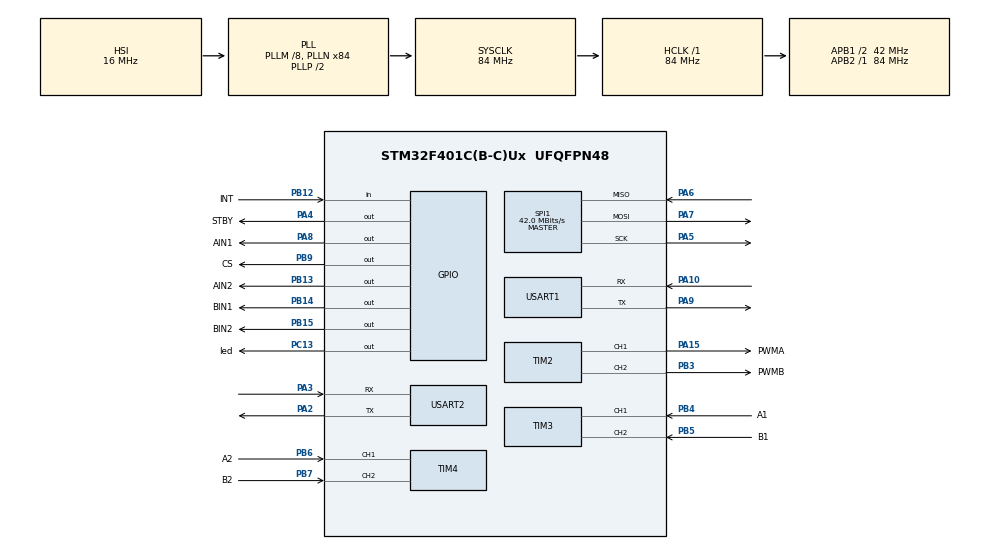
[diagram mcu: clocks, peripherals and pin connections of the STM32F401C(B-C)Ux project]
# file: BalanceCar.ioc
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Mcu.Family=STM32F4
Mcu.Name=STM32F401C(B-C)Ux
Mcu.Package=UFQFPN48
NVIC.PriorityGroup=NVIC_PRIORITYGROUP_4
PA10.Mode=Asynchronous
PA10.Signal=USART1_RX
PA15.GPIO_Label=PWMA
PA15.Signal=S_TIM2_CH1_ETR
PA2.Mode=Asynchronous
PA2.Signal=USART2_TX
PA3.Mode=Asynchronous
PA3.Signal=USART2_RX
PA4.GPIO_Label=STBY
PA4.Signal=GPIO_Output
PA5.Mode=Full_Duplex_Master
PA5.Signal=SPI1_SCK
PA6.Mode=Full_Duplex_Master
PA6.Signal=SPI1_MISO
PA7.Mode=Full_Duplex_Master
PA7.Signal=SPI1_MOSI
PA8.GPIO_Label=AIN1
PA8.Signal=GPIO_Output
PA9.Mode=Asynchronous
PA9.Signal=USART1_TX
PB12.GPIO_Label=INT
PB12.GPIO_PuPd=GPIO_PULLUP
PB12.Signal=GPIO_Input
PB13.GPIO_Label=AIN2
PB13.Signal=GPIO_Output
PB14.GPIO_Label=BIN1
PB14.Signal=GPIO_Output
PB15.GPIO_Label=BIN2
PB15.Signal=GPIO_Output
PB3.GPIO_Label=PWMB
PB3.Signal=S_TIM2_CH2
PB4.GPIO_Label=A1
PB4.Signal=S_TIM3_CH1
PB5.GPIO_Label=B1
PB5.Signal=S_TIM3_CH2
PB6.GPIO_Label=A2
PB6.Signal=S_TIM4_CH1
PB7.GPIO_Label=B2
PB7.Signal=S_TIM4_CH2
PB9.GPIO_Label=CS
PB9.Signal=GPIO_Output
PC13-ANTI_TAMP.GPIO_Label=led
PC13-ANTI_TAMP.Signal=GPIO_Output
PC14-OSC32_IN.Mode=LSE-External-Oscillator
PC14-OSC32_IN.Signal=RCC_OSC32_IN
PC15-OSC32_OUT.Mode=LSE-External-Oscillator
PC15-OSC32_OUT.Signal=RCC_OSC32_OUT
PH0\ -\ OSC_IN.Mode=HSE-External-Oscillator
PH0\ -\ OSC_IN.Signal=RCC_OSC_IN
PH1\ -\ OSC_OUT.Mode=HSE-External-Oscillator
PH1\ -\ OSC_OUT.Signal=RCC_OSC_OUT
ProjectManager.HeapSize=0x200
ProjectManager.StackSize=0x400
ProjectManager.TargetToolchain=Makefile
RCC.48MHZClocksFreq_Value=42000000
RCC.AHBFreq_Value=84000000
RCC.APB1CLKDivider=RCC_HCLK_DIV2
RCC.APB1Freq_Value=42000000
RCC.APB1TimFreq_Value=84000000
RCC.APB2Freq_Value=84000000
RCC.APB2TimFreq_Value=84000000
RCC.CortexFreq_Value=84000000
RCC.HCLKFreq_Value=84000000
RCC.HSE_VALUE=25000000
RCC.HSI_VALUE=16000000
RCC.PLLM=8
RCC.PLLN=84
RCC.SYSCLKFreq_VALUE=84000000
RCC.SYSCLKSource=RCC_SYSCLKSOURCE_PLLCLK
RCC.VCOOutputFreq_Value=168000000
SH.S_TIM2_CH1_ETR.0=TIM2_CH1,PWM Generation1 CH1
SH.S_TIM2_CH2.0=TIM2_CH2,PWM Generation2 CH2
SH.S_TIM3_CH1.0=TIM3_CH1,Encoder_Interface
SH.S_TIM3_CH2.0=TIM3_CH2,Encoder_Interface
SH.S_TIM4_CH1.0=TIM4_CH1,Encoder_Interface
SH.S_TIM4_CH2.0=TIM4_CH2,Encoder_Interface
SPI1.CalculateBaudRate=42.0 MBits/s
SPI1.Direction=SPI_DIRECTION_2LINES
SPI1.Mode=SPI_MODE_MASTER
SPI1.VirtualType=VM_MASTER
TIM2.Channel-PWM\ Generation1\ CH1=TIM_CHANNEL_1
TIM2.Channel-PWM\ Generation2\ CH2=TIM_CHANNEL_2
USART1.VirtualMode=VM_ASYNC
USART2.VirtualMode=VM_ASYNC
board=custom

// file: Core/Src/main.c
/* USER CODE BEGIN Header */
/**
  ******************************************************************************
  * @file           : main.c
  * @brief          : Main program body
  ******************************************************************************
  * @attention
  *
  * Copyright (c) 2024 STMicroelectronics.
  * All rights reserved.
  *
  * This software is licensed under terms that can be found in the LICENSE file
  * in the root directory of this software component.
  * If no LICENSE file comes with this software, it is provided AS-IS.
  *
  ******************************************************************************
  */
/* USER CODE END Header */
#include "main.h"
#include "spi.h"
#include "tim.h"
#include "usart.h"
#include "gpio.h"
#include "stdio.h"

void SystemClock_Config(void);

int main(void)
{

  /* MCU Configuration--------------------------------------------------------*/

  /* Reset of all peripherals, Initializes the Flash interface and the Systick. */
  HAL_Init();

  /* Configure the system clock */
  SystemClock_Config();

  /* Initialize all configured peripherals */
  MX_GPIO_Init();
  MX_SPI1_Init();
  MX_TIM2_Init();
  MX_TIM3_Init();
  MX_TIM4_Init();
  MX_USART1_UART_Init();
  MX_USART2_UART_Init();

  /* Infinite loop */
  /* USER CODE BEGIN WHILE */
  while (1)
  {

      printf("HELLO\n");
      HAL_Delay(1000);
    /* USER CODE END WHILE */

  }
}

void SystemClock_Config(void)
{
  RCC_OscInitTypeDef RCC_OscInitStruct = {0};
  RCC_ClkInitTypeDef RCC_ClkInitStruct = {0};

  /** Configure the main internal regulator output voltage
  */
  __HAL_RCC_PWR_CLK_ENABLE();
  __HAL_PWR_VOLTAGESCALING_CONFIG(PWR_REGULATOR_VOLTAGE_SCALE2);

  /** Initializes the RCC Oscillators according to the specified parameters
  * in the RCC_OscInitTypeDef structure.
  */
  RCC_OscInitStruct.OscillatorType = RCC_OSCILLATORTYPE_HSI;
  RCC_OscInitStruct.HSIState = RCC_HSI_ON;
  RCC_OscInitStruct.HSICalibrationValue = RCC_HSICALIBRATION_DEFAULT;
  RCC_OscInitStruct.PLL.PLLState = RCC_PLL_ON;
  RCC_OscInitStruct.PLL.PLLSource = RCC_PLLSOURCE_HSI;
  RCC_OscInitStruct.PLL.PLLM = 8;
  RCC_OscInitStruct.PLL.PLLN = 84;
  RCC_OscInitStruct.PLL.PLLP = RCC_PLLP_DIV2;
  RCC_OscInitStruct.PLL.PLLQ = 4;
  if (HAL_RCC_OscConfig(&RCC_OscInitStruct) != HAL_OK)
  {
    Error_Handler();
  }

  /** Initializes the CPU, AHB and APB buses clocks
  */
  RCC_ClkInitStruct.ClockType = RCC_CLOCKTYPE_HCLK|RCC_CLOCKTYPE_SYSCLK
                              |RCC_CLOCKTYPE_PCLK1|RCC_CLOCKTYPE_PCLK2;
  RCC_ClkInitStruct.SYSCLKSource = RCC_SYSCLKSOURCE_PLLCLK;
  RCC_ClkInitStruct.AHBCLKDivider = RCC_SYSCLK_DIV1;
  RCC_ClkInitStruct.APB1CLKDivider = RCC_HCLK_DIV2;
  RCC_ClkInitStruct.APB2CLKDivider = RCC_HCLK_DIV1;

  if (HAL_RCC_ClockConfig(&RCC_ClkInitStruct, FLASH_LATENCY_2) != HAL_OK)
  {
    Error_Handler();
  }
}

void Error_Handler(void)
{
  __disable_irq();
  while (1)
  {
  }
}
